# GameCube register map
Vendor: Nintendo
Registers are 16-bit, access not given, no defined reset value unless marked. A register's access mark holds for its fields unless they carry their own. Offsets are from the block's base; lines under a group give offsets from that group; [hi:lo] are bit positions; {n}, {i} and the like mark numbered series; 'fields as' and 'values as' point back to an identical list; <NAME> marks a mode.

## Memory map
0xCC000000 CP — Command Processor
0xCC003000 PI — Processor Interface
0xCC006000 DI — DVD Interface

## CP — Command Processor
Base 0xCC000000
0x40 XF_RASBUSY_L
0x42 XF_RASBUSY_H
0x44 XF_CLKS_L
0x46 XF_CLKS_H
0x48 XF_WAIT_IN_L
0x4A XF_WAIT_IN_H
0x4C XF_WAIT_OUT_L
0x4E XF_WAIT_OUT_H
0x50 VCACHE_METRIC_CHECK_L
0x52 VCACHE_METRIC_CHECK_H
0x54 VCACHE_METRIC_MISS_L
0x56 VCACHE_METRIC_MISS_H
0x58 VCACHE_METRIC_STALL_L
0x5A VCACHE_METRIC_STALL_H
0x60 CLKS_PER_VTX_IN_L
0x62 CLKS_PER_VTX_IN_H
0x64 CLKS_PER_VTX_OUT

## PI — Processor Interface
Base 0xCC003000
0x24 di_control 32-bit

## DI — DVD Interface
Base 0xCC006000
0x00 status 32-bit
  [6] break_complete_asserted ro, [6] ack_break_complete wo, [5] break_complete_mask, [4] transfer_complete_asserted ro, [4] ack_transfer_complete wo, [3] transfer_complete_mask, [2] device_error_asserted ro, [2] ack_device_error wo, [1] device_error_mask, [0] break_pending ro, [0] request_break wo
0x04 cover 32-bit
  [2] asserted ro, [2] ack wo, [1] mask, [0] state
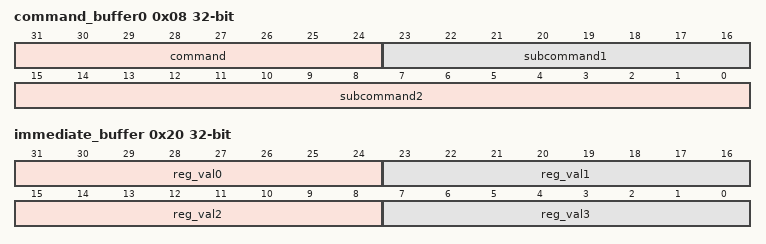
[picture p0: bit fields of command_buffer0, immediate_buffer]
0x08 command_buffer0 32-bit
  [31:24] command, [23:16] subcommand1, [15:0] subcommand2
0x0C command_buffer1 32-bit
0x10 command_buffer2 32-bit
0x14 dma_address 32-bit
0x18 dma_length 32-bit
0x1C control 32-bit
  [2] access
    0=read; 1=write
  [1] dma
  [0] transfer_pending ro
  [0] start_transfer wo
0x20 immediate_buffer 32-bit
  [31-8n:24-8n] reg_val{n} (n=0..3)
0x24 config 32-bit ro
